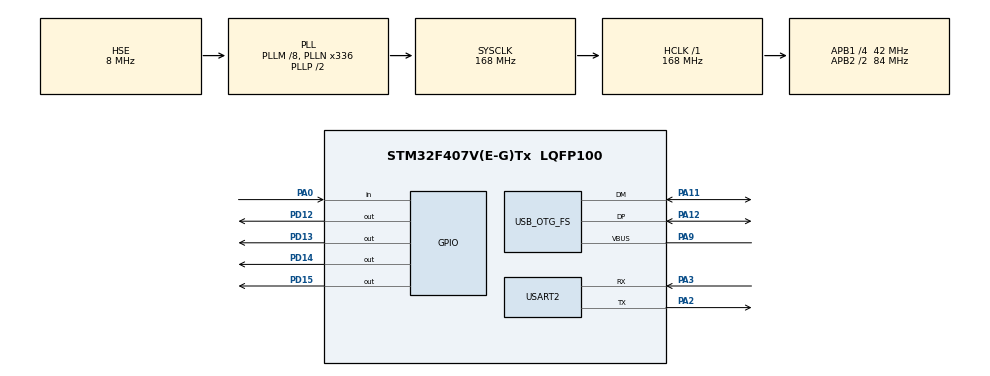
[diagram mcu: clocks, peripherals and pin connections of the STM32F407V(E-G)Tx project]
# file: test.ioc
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Dma.Request0=USART2_RX
Dma.Request1=USART2_TX
Dma.USART2_RX.0.Channel=DMA_CHANNEL_4
Dma.USART2_RX.0.Direction=DMA_PERIPH_TO_MEMORY
Dma.USART2_RX.0.FIFOMode=DMA_FIFOMODE_DISABLE
Dma.USART2_RX.0.Instance=DMA1_Stream5
Dma.USART2_RX.0.MemDataAlignment=DMA_MDATAALIGN_BYTE
Dma.USART2_RX.0.MemInc=DMA_MINC_ENABLE
Dma.USART2_RX.0.Mode=DMA_NORMAL
Dma.USART2_RX.0.PeriphDataAlignment=DMA_PDATAALIGN_BYTE
Dma.USART2_RX.0.PeriphInc=DMA_PINC_DISABLE
Dma.USART2_RX.0.Priority=DMA_PRIORITY_LOW
Dma.USART2_TX.1.Channel=DMA_CHANNEL_4
Dma.USART2_TX.1.Direction=DMA_MEMORY_TO_PERIPH
Dma.USART2_TX.1.FIFOMode=DMA_FIFOMODE_DISABLE
Dma.USART2_TX.1.Instance=DMA1_Stream6
Dma.USART2_TX.1.MemDataAlignment=DMA_MDATAALIGN_BYTE
Dma.USART2_TX.1.MemInc=DMA_MINC_ENABLE
Dma.USART2_TX.1.Mode=DMA_NORMAL
Dma.USART2_TX.1.PeriphDataAlignment=DMA_PDATAALIGN_BYTE
Dma.USART2_TX.1.PeriphInc=DMA_PINC_DISABLE
Dma.USART2_TX.1.Priority=DMA_PRIORITY_LOW
Mcu.Family=STM32F4
Mcu.Name=STM32F407V(E-G)Tx
Mcu.Package=LQFP100
NVIC.DMA1_Stream5_IRQn=true\:0\:0\:false
NVIC.DMA1_Stream6_IRQn=true\:0\:0\:false
NVIC.OTG_FS_IRQn=true\:0\:0\:false
NVIC.PriorityGroup=NVIC_PRIORITYGROUP_4
NVIC.USART2_IRQn=true\:0\:0\:false
PA0-WKUP.Signal=GPIO_Input
PA11.Mode=Device_Only
PA11.Signal=USB_OTG_FS_DM
PA12.Mode=Device_Only
PA12.Signal=USB_OTG_FS_DP
PA2.Mode=Asynchronous
PA2.Signal=USART2_TX
PA3.Mode=Asynchronous
PA3.Signal=USART2_RX
PA9.Mode=Activate_VBUS
PA9.Signal=USB_OTG_FS_VBUS
PD12.Signal=GPIO_Output
PD13.Signal=GPIO_Output
PD14.Signal=GPIO_Output
PD15.Signal=GPIO_Output
PH0-OSC_IN.Mode=HSE-External-Oscillator
PH0-OSC_IN.Signal=RCC_OSC_IN
PH1-OSC_OUT.Mode=HSE-External-Oscillator
PH1-OSC_OUT.Signal=RCC_OSC_OUT
ProjectManager.TargetToolchain=MDK-ARM V5
RCC.48MHZClocksFreq_Value=48000000
RCC.AHBFreq_Value=168000000
RCC.APB1CLKDivider=RCC_HCLK_DIV4
RCC.APB1Freq_Value=42000000
RCC.APB1TimFreq_Value=84000000
RCC.APB2CLKDivider=RCC_HCLK_DIV2
RCC.APB2Freq_Value=84000000
RCC.APB2TimFreq_Value=168000000
RCC.CortexFreq_Value=21000000
RCC.HCLKFreq_Value=168000000
RCC.HSE_VALUE=8000000
RCC.HSI_VALUE=16000000
RCC.LSE_VALUE=32768
RCC.PLLM=8
RCC.PLLN=336
RCC.PLLQ=7
RCC.SYSCLKFreq_VALUE=168000000
RCC.SYSCLKSource=RCC_SYSCLKSOURCE_PLLCLK
RCC.VCOOutputFreq_Value=336000000
USB_DEVICE.CLASS_NAME-CDC_FS=CDC
USB_DEVICE.USBD_HandleTypeDef-CDC_FS=hUsbDeviceFS
USB_DEVICE.VirtualMode-CDC_FS=Cdc
USB_DEVICE.VirtualModeFS=Cdc_FS
USB_OTG_FS.VirtualMode=Device_Only
VP_USB_DEVICE_VS_USB_DEVICE_CDC_FS.Mode=CDC_FS

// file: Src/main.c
/**
  ******************************************************************************
  * File Name          : main.c
  * Date               : 31/05/2015 23:15:34
  * Description        : Main program body
  ******************************************************************************
  *
  * COPYRIGHT(c) 2015 STMicroelectronics
  *
  * Redistribution and use in source and binary forms, with or without modification,
  * are permitted provided that the following conditions are met:
  *   1. Redistributions of source code must retain the above copyright notice,
  *      this list of conditions and the following disclaimer.
  *   2. Redistributions in binary form must reproduce the above copyright notice,
  *      this list of conditions and the following disclaimer in the documentation
  *      and/or other materials provided with the distribution.
  *   3. Neither the name of STMicroelectronics nor the names of its contributors
  *      may be used to endorse or promote products derived from this software
  *      without specific prior written permission.
  *
  * THIS SOFTWARE IS PROVIDED BY THE COPYRIGHT HOLDERS AND CONTRIBUTORS "AS IS"
  * AND ANY EXPRESS OR IMPLIED WARRANTIES, INCLUDING, BUT NOT LIMITED TO, THE
  * IMPLIED WARRANTIES OF MERCHANTABILITY AND FITNESS FOR A PARTICULAR PURPOSE ARE
  * DISCLAIMED. IN NO EVENT SHALL THE COPYRIGHT HOLDER OR CONTRIBUTORS BE LIABLE
  * FOR ANY DIRECT, INDIRECT, INCIDENTAL, SPECIAL, EXEMPLARY, OR CONSEQUENTIAL
  * DAMAGES (INCLUDING, BUT NOT LIMITED TO, PROCUREMENT OF SUBSTITUTE GOODS OR
  * SERVICES; LOSS OF USE, DATA, OR PROFITS; OR BUSINESS INTERRUPTION) HOWEVER
  * CAUSED AND ON ANY THEORY OF LIABILITY, WHETHER IN CONTRACT, STRICT LIABILITY,
  * OR TORT (INCLUDING NEGLIGENCE OR OTHERWISE) ARISING IN ANY WAY OUT OF THE USE
  * OF THIS SOFTWARE, EVEN IF ADVISED OF THE POSSIBILITY OF SUCH DAMAGE.
  *
  ******************************************************************************
  */

#include "stm32f4xx_hal.h"
#include "usb_device.h"
#include "usart.h"
#include "usbd_cdc_if.h"

void SystemClock_Config(void);
static void MX_GPIO_Init(void);
static void MX_DMA_Init(void);

#define DEBUG
#ifdef DEBUG
	int fputc(int c, FILE *stream)
	{
		 return(ITM_SendChar(c));
	}
#endif

int main(void)
{

  /* MCU Configuration----------------------------------------------------------*/

  /* Reset of all peripherals, Initializes the Flash interface and the Systick. */
  HAL_Init();

  /* Configure the system clock */
  SystemClock_Config();

  /* Initialize all configured peripherals */
  MX_GPIO_Init();
  MX_DMA_Init();
  MX_USART2_UART_Init();
  MX_USB_DEVICE_Init();

  /* Infinite loop */
  /* USER CODE BEGIN WHILE */

	HAL_GPIO_WritePin(GPIOD,GPIO_PIN_13,GPIO_PIN_SET);
	HAL_GPIO_WritePin(GPIOD,GPIO_PIN_14,GPIO_PIN_RESET);
	char x;

	/* Enabling exception for debugging*/
	SCB->CCR |= (1<<4) | (1<<3);
	SCB->SHCSR |= 0x00070000;

  while (1)
  {
  /* USER CODE END WHILE */

		if(USART_GetChar(&x) == true)
			CDC_Transmit_FS(&x,1);

  }

}

/** System Clock Configuration
*/
void SystemClock_Config(void)
{

  RCC_OscInitTypeDef RCC_OscInitStruct;
  RCC_ClkInitTypeDef RCC_ClkInitStruct;

  __PWR_CLK_ENABLE();

  __HAL_PWR_VOLTAGESCALING_CONFIG(PWR_REGULATOR_VOLTAGE_SCALE1);

  RCC_OscInitStruct.OscillatorType = RCC_OSCILLATORTYPE_HSE;
  RCC_OscInitStruct.HSEState = RCC_HSE_ON;
  RCC_OscInitStruct.PLL.PLLState = RCC_PLL_ON;
  RCC_OscInitStruct.PLL.PLLSource = RCC_PLLSOURCE_HSE;
  RCC_OscInitStruct.PLL.PLLM = 8;
  RCC_OscInitStruct.PLL.PLLN = 336;
  RCC_OscInitStruct.PLL.PLLP = RCC_PLLP_DIV2;
  RCC_OscInitStruct.PLL.PLLQ = 7;
  HAL_RCC_OscConfig(&RCC_OscInitStruct);

  RCC_ClkInitStruct.ClockType = RCC_CLOCKTYPE_SYSCLK|RCC_CLOCKTYPE_PCLK1
                              |RCC_CLOCKTYPE_PCLK2;
  RCC_ClkInitStruct.SYSCLKSource = RCC_SYSCLKSOURCE_PLLCLK;
  RCC_ClkInitStruct.AHBCLKDivider = RCC_SYSCLK_DIV1;
  RCC_ClkInitStruct.APB1CLKDivider = RCC_HCLK_DIV4;
  RCC_ClkInitStruct.APB2CLKDivider = RCC_HCLK_DIV2;
  HAL_RCC_ClockConfig(&RCC_ClkInitStruct, FLASH_LATENCY_5);

}

void MX_DMA_Init(void)
{
  /* DMA controller clock enable */
  __DMA1_CLK_ENABLE();

  /* DMA interrupt init */
  HAL_NVIC_SetPriority(DMA1_Stream6_IRQn, 0, 0);
  HAL_NVIC_EnableIRQ(DMA1_Stream6_IRQn);
  HAL_NVIC_SetPriority(DMA1_Stream5_IRQn, 0, 0);
  HAL_NVIC_EnableIRQ(DMA1_Stream5_IRQn);

}

/** Configure pins as
        * Analog
        * Input
        * Output
        * EVENT_OUT
        * EXTI
*/
void MX_GPIO_Init(void)
{

  GPIO_InitTypeDef GPIO_InitStruct;

  /* GPIO Ports Clock Enable */
  __GPIOH_CLK_ENABLE();
  __GPIOA_CLK_ENABLE();
  __GPIOD_CLK_ENABLE();

  /*Configure GPIO pin : PA0 */
  GPIO_InitStruct.Pin = GPIO_PIN_0;
  GPIO_InitStruct.Mode = GPIO_MODE_INPUT;
  GPIO_InitStruct.Pull = GPIO_NOPULL;
  HAL_GPIO_Init(GPIOA, &GPIO_InitStruct);

  /*Configure GPIO pins : PD12 PD13 PD14 PD15 */
  GPIO_InitStruct.Pin = GPIO_PIN_12|GPIO_PIN_13|GPIO_PIN_14|GPIO_PIN_15;
  GPIO_InitStruct.Mode = GPIO_MODE_OUTPUT_PP;
  GPIO_InitStruct.Pull = GPIO_NOPULL;
  GPIO_InitStruct.Speed = GPIO_SPEED_LOW;
  HAL_GPIO_Init(GPIOD, &GPIO_InitStruct);

}

/************************ (C) COPYRIGHT STMicroelectronics *****END OF FILE****/

/*void HardFault_Handler(void){

	HAL_GPIO_WritePin(GPIOD,GPIO_PIN_12,GPIO_PIN_SET);

}*/

//__asm  void HardFault_Handler(void)
//{
//			tst lr, #4
//			ite eq
//			mrseq r0, msp
//			mrsne r0, psp
//			ldr r1, [r0, #24]
//			ldr r2, handler2_address_const
//			bx r2
//handler2_address_const
//.word hard_fault_handler_c
//ENDP
//}
void hard_fault_handler_c (unsigned int * hardfault_args);

//__asm void HardFault_Handler(void)
//{
//   TST lr, #4
//   ITE EQ
//   MRSEQ r0, MSP
//   MRSNE r0, PSP
//   B __cpp(hard_fault_handler_c)
//}

//__asm void HardFault_Handler(void)
//{
//	IMPORT hard_fault_handler_c
//	TST LR, #4
//	ITE EQ
//	MRSEQ R0, MSP
//	MRSNE R0, PSP
//	B hard_fault_handler_c
//}
